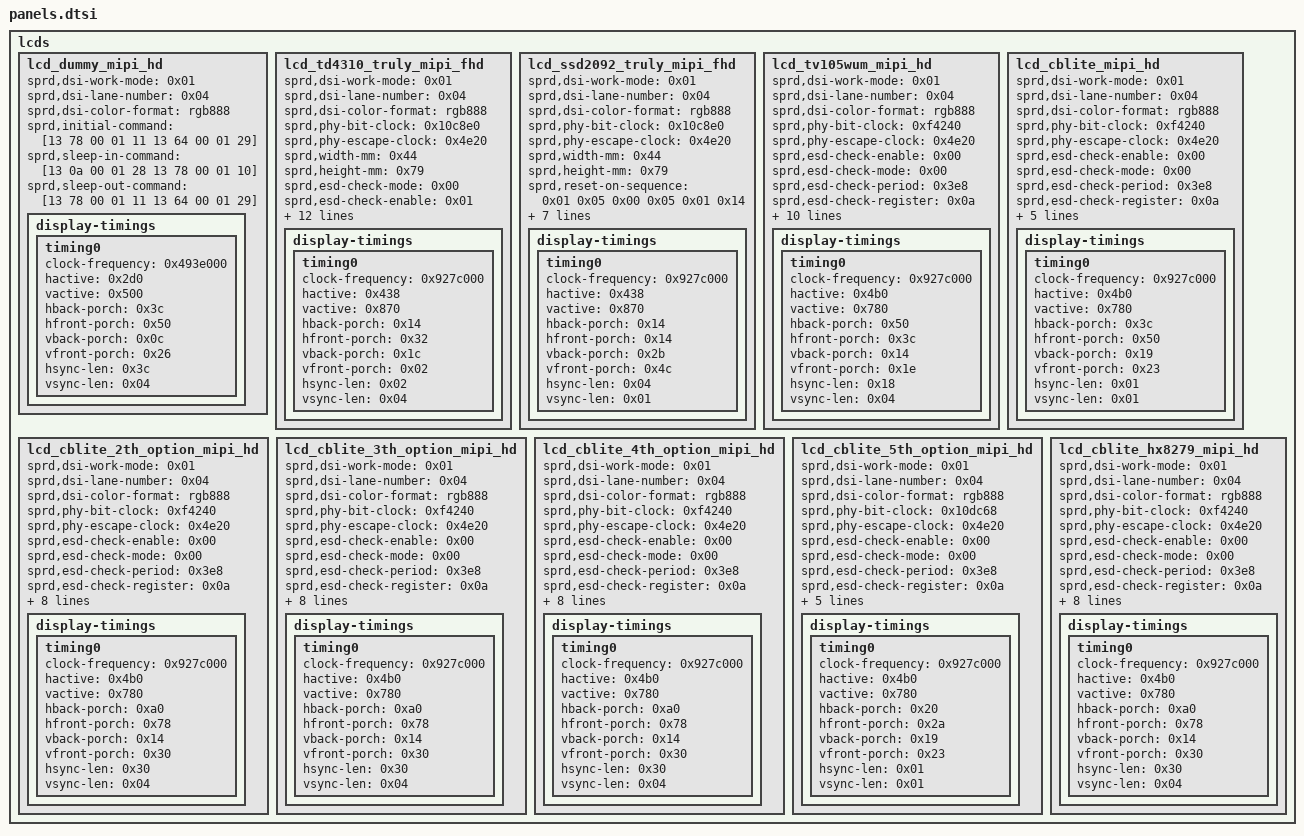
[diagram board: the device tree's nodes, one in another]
/*
 * iclass-c8pro hardware description; included in place from the board DTS.
 * Copyright (C) 2026 Evarentha - Linux 5.15 board port changes.
 */

	lcds {

		lcd_dummy_mipi_hd: lcd_dummy_mipi_hd {
			sprd,dsi-work-mode = <0x01>;
			sprd,dsi-lane-number = <0x04>;
			sprd,dsi-color-format = "rgb888";
			sprd,initial-command = [13 78 00 01 11 13 64 00 01 29];
			sprd,sleep-in-command = [13 0a 00 01 28 13 78 00 01 10];
			sprd,sleep-out-command = [13 78 00 01 11 13 64 00 01 29];
			phandle = <0x1ee>;

			display-timings {

				timing0 {
					clock-frequency = <0x493e000>;
					hactive = <0x2d0>;
					vactive = <0x500>;
					hback-porch = <0x3c>;
					hfront-porch = <0x50>;
					vback-porch = <0x0c>;
					vfront-porch = <0x26>;
					hsync-len = <0x3c>;
					vsync-len = <0x04>;
				};
			};
		};

		lcd_td4310_truly_mipi_fhd: lcd_td4310_truly_mipi_fhd {
			sprd,dsi-work-mode = <0x01>;
			sprd,dsi-lane-number = <0x04>;
			sprd,dsi-color-format = "rgb888";
			sprd,phy-bit-clock = <0x10c8e0>;
			sprd,phy-escape-clock = <0x4e20>;
			sprd,width-mm = <0x44>;
			sprd,height-mm = <0x79>;
			sprd,esd-check-mode = <0x00>;
			sprd,esd-check-enable = <0x01>;
			sprd,esd-check-register = <0x0a>;
			sprd,esd-check-value = <0x1c>;
			sprd,reset-on-sequence = <0x01 0x05 0x00 0x05 0x01 0x14>;
			sprd,reset-off-sequence = <0x00 0x05>;
			sprd,use-dcs-write;
			sprd,initial-command = [39 00 00 02 b0 00 39 00 00 04 b3 31 00 06 39 00 00 02 b4 00 39 00 00 06 b6 33 5b 81 72 00 39 00 00 08 b8 57 3d 19 1e 0a 50 50 39 00 00 08 b9 6f 3d 28 3c 14 c8 c8 39 00 00 08 ba b5 33 41 64 23 a0 a0 39 00 00 03 bb 14 14 39 00 00 03 bc 37 32 39 00 00 03 bd 64 32 39 00 00 02 be 04 39 00 00 02 c0 00 39 00 00 31 c1 04 40 00 00 26 15 19 0b 63 d2 d9 9a 73 ef bd e7 5c 6b 93 4d 22 18 8b 2a 41 00 00 00 00 00 00 00 00 00 40 02 22 1b 06 03 00 0f ff 00 01 00 00 00 39 00 00 19 c2 01 f8 70 08 68 08 0c 10 00 08 30 00 00 00 00 00 00 00 00 08 00 00 00 00 39 00 00 3f c3 86 d8 6d 86 d0 00 00 00 00 00 44 24 42 00 00 48 84 88 00 00 01 01 03 28 00 01 00 01 00 00 19 00 19 00 00 00 19 00 19 00 00 00 00 00 00 00 00 00 32 00 32 00 5a 02 00 00 00 00 00 00 40 00 39 00 00 15 c4 70 00 00 00 11 11 00 00 00 02 02 31 01 00 00 00 02 01 01 01 39 00 00 09 c5 08 00 00 00 00 70 00 00 39 00 00 40 c6 42 21 21 05 3d 05 3d 01 02 01 02 05 05 00 00 05 05 0b 0c 05 42 00 6e 61 00 00 00 00 00 00 00 00 00 00 00 00 00 00 00 00 00 00 00 00 00 00 00 00 00 00 00 00 00 00 00 00 00 00 00 00 00 00 00 39 00 00 27 c7 00 1f 30 43 52 5c 72 80 8b 95 45 4f 5c 70 79 85 90 93 bf 00 1f 30 43 52 5c 72 80 8b 95 45 4f 5c 70 79 85 90 93 bf 39 00 00 38 c8 00 00 00 00 00 fc 00 00 00 00 00 fc 00 00 00 00 00 fc 00 00 00 00 00 fc 00 00 00 00 00 fc 00 00 00 00 00 fc 00 00 00 00 00 fc 00 00 00 00 00 fc 00 00 00 00 00 fc 00 39 00 00 14 c9 00 00 00 00 00 fc 00 00 00 00 00 fc 00 00 00 00 00 fc 00 39 00 00 2c ca 1c fc fc fc 00 00 00 00 00 00 00 00 00 00 00 00 00 00 00 00 00 00 00 00 00 00 00 00 00 00 00 00 00 00 00 00 00 00 00 00 00 00 00 39 00 00 1c cb ff ff ff ff 0f 00 08 00 01 00 31 f0 40 08 00 00 00 00 00 00 00 00 00 00 00 00 00 39 00 00 03 cc 02 01 39 00 00 27 cd 25 00 28 00 28 00 5c 02 df df e0 e0 d6 d6 e0 e0 01 00 00 00 32 00 32 00 5d 02 24 24 01 33 00 33 00 5e 02 24 24 a2 39 00 00 1a ce 5d 40 49 53 59 5e 63 68 6e 74 7e 8a 98 a8 bb d0 ff 04 00 04 04 42 00 69 5a 39 00 00 03 cf 4a 1d 39 00 00 14 d0 33 57 d4 31 01 10 10 10 19 19 00 00 00 00 00 00 00 6d 65 39 00 00 02 d1 00 39 00 00 16 d3 1b 3b bb 77 77 77 bb b3 33 00 00 6d 6e c7 c7 33 bb f2 fd c6 0b 39 00 00 0b d5 03 00 00 02 0e 02 0e 01 00 00 39 00 00 02 d6 01 39 00 00 22 d7 f6 ff 03 05 41 24 80 1f c7 1f 1b 00 0c 07 20 00 00 00 00 00 0c 00 1f 00 fc 00 00 ab 67 7e 5d 26 00 39 00 00 08 d9 00 16 14 3f 0f 57 04 39 00 00 05 dd 30 06 23 65 39 00 00 05 de 00 3f ff 90 39 00 00 02 ea 1f 39 00 00 04 ee 41 51 00 39 00 00 04 f1 00 00 00 15 00 00 02 35 00 05 14 00 01 29 05 64 00 01 11];
			sprd,sleep-in-command = [13 0a 00 01 28 13 14 00 01 10];
			sprd,sleep-out-command = [13 78 00 01 11 13 32 00 01 29];
			phandle = <0x1ef>;

			display-timings {

				timing0 {
					clock-frequency = <0x927c000>;
					hactive = <0x438>;
					vactive = <0x870>;
					hback-porch = <0x14>;
					hfront-porch = <0x32>;
					vback-porch = <0x1c>;
					vfront-porch = <0x02>;
					hsync-len = <0x02>;
					vsync-len = <0x04>;
				};
			};
		};

		lcd_ssd2092_truly_mipi_fhd: lcd_ssd2092_truly_mipi_fhd {
			sprd,dsi-work-mode = <0x01>;
			sprd,dsi-lane-number = <0x04>;
			sprd,dsi-color-format = "rgb888";
			sprd,phy-bit-clock = <0x10c8e0>;
			sprd,phy-escape-clock = <0x4e20>;
			sprd,width-mm = <0x44>;
			sprd,height-mm = <0x79>;
			sprd,reset-on-sequence = <0x01 0x05 0x00 0x05 0x01 0x14>;
			sprd,reset-off-sequence = <0x00 0x05>;
			sprd,initial-command = [29 00 00 03 b5 00 00 29 00 00 03 b3 03 96 29 00 00 03 b4 21 ff 29 00 00 03 e1 00 00 29 00 00 04 e1 03 00 10 29 00 00 03 b0 04 01 29 00 00 03 b0 07 14 29 00 00 03 c6 04 2d 29 00 00 03 b9 0e 44 29 00 00 03 c1 0c 26 29 00 00 03 c1 08 99 29 00 00 03 b9 23 00 29 00 00 03 c2 04 0f 29 00 00 03 b9 11 22 29 00 00 03 b9 12 22 29 00 00 03 b9 13 22 29 00 00 03 b3 19 0b 29 00 00 03 b0 3d c8 29 00 00 03 b3 0f 20 29 00 00 02 36 02 29 00 00 03 c7 01 09 29 00 00 03 b3 15 80 29 00 00 03 b3 1e 02 29 00 00 03 b3 14 c0 29 00 00 03 b3 16 50 29 00 00 03 b3 1c e4 29 00 00 03 b3 28 09 29 00 00 03 b3 24 19 29 00 00 03 b0 12 00 29 00 00 03 b0 13 14 29 00 00 03 b0 1a 00 29 00 00 03 b0 1b 14 29 00 00 03 c1 0d 87 29 00 00 03 c1 0e 87 29 00 00 17 c3 00 10 2e 3e 48 5e 6b 7a 83 97 a3 a8 a5 ac ad b5 c1 c4 4e 4f 59 5a 29 00 00 17 c3 15 10 2e 3e 48 5e 6b 7a 83 97 a3 a8 a5 ac ad b5 c1 c4 4e 4f 59 5a 29 00 00 03 bb 01 8a 29 00 00 03 bb 02 23 29 00 00 03 bb 03 bc 29 00 00 03 bb 04 c0 29 00 00 03 bb 05 19 29 00 00 03 bb 06 37 29 00 00 03 bb 07 ee 29 00 00 03 bb 08 dd 29 00 00 03 bb 09 cc 29 00 00 03 bb 0a 36 29 00 00 03 bb 0b 70 29 00 00 03 bb 0c 00 29 00 00 03 bb 0d 8a 29 00 00 03 bb 0e 23 29 00 00 03 bb 0f bc 29 00 00 03 bb 10 c0 29 00 00 03 bb 11 18 29 00 00 03 bb 12 a7 29 00 00 03 bb 13 ee 29 00 00 03 bb 14 dd 29 00 00 03 bb 15 cc 29 00 00 03 bb 16 36 29 00 00 03 bb 17 70 29 00 00 03 bb 18 00 29 00 00 03 bb 31 01 29 00 00 03 bd 00 f0 29 00 00 03 bd 01 f0 29 00 00 03 bd 02 f0 29 00 00 03 bd 03 f0 29 00 00 03 bd 1a 02 29 00 00 03 bd 1b 24 29 00 00 03 bd 1d 01 29 00 00 03 bd 1e 01 29 00 00 03 bd 21 00 29 00 00 03 bd 1f 79 29 00 00 03 bd 20 14 29 00 00 03 bd 22 89 29 00 00 03 bd 23 13 29 00 00 03 bd 24 35 29 00 00 03 bd 26 01 29 00 00 03 bd 27 01 29 00 00 03 bd 2a 00 29 00 00 03 bd 28 79 29 00 00 03 bd 29 14 29 00 00 03 bd 2b 89 29 00 00 03 bd 2c 33 29 00 00 03 bd 2d 33 29 00 00 03 bd 2e 11 29 00 00 03 bd 2f 11 29 00 00 03 bd 31 22 29 00 00 03 bd 32 01 29 00 00 03 bd 33 04 29 00 00 03 bd 34 11 29 00 00 03 bd 35 11 29 00 00 03 bd 37 22 29 00 00 03 bd 38 01 29 00 00 03 bd 39 04 29 00 00 03 bd 3a 1e 29 00 00 03 bd 3b 1e 29 00 00 03 bd 3c 1e 29 00 00 03 bd 3d 1e 29 00 00 03 bd 40 aa 29 00 00 03 bd 42 1e 29 00 00 03 bd 43 1e 29 00 00 03 bd 44 1e 29 00 00 03 bd 45 1e 29 00 00 03 bd 48 aa 29 00 00 03 ba 02 05 29 00 00 03 ba 03 01 29 00 00 03 bc 1e 71 29 00 00 03 bc 24 83 29 00 00 03 b8 03 a9 29 00 00 03 ba 15 41 29 00 00 03 bb 19 8a 29 00 00 03 bb 1a 32 29 00 00 03 bb 1b bc 29 00 00 03 bb 1c c2 29 00 00 03 bb 1d 39 29 00 00 03 bb 1e 37 29 00 00 03 bb 1f ee 29 00 00 03 bb 20 dd 29 00 00 03 bb 21 cc 29 00 00 03 bb 22 36 29 00 00 03 bb 23 70 29 00 00 03 bb 24 00 29 00 00 03 bb 25 8a 29 00 00 03 bb 26 32 29 00 00 03 bb 27 bc 29 00 00 03 bb 28 c2 29 00 00 03 bb 29 38 29 00 00 03 bb 2a a7 29 00 00 03 bb 2b ee 29 00 00 03 bb 2c dd 29 00 00 03 bb 2d cc 29 00 00 03 bb 2e 36 29 00 00 03 bb 2f 70 29 00 00 03 bb 30 00 29 00 00 03 b8 15 a2 29 00 00 03 b0 39 00 29 00 00 04 c6 00 03 40 29 00 00 03 b3 18 00 29 00 00 03 ba 17 28 29 00 00 03 ba 23 15 29 00 00 03 b0 06 2c 29 00 00 03 ba 17 28 29 00 00 03 ba 23 15 29 00 00 03 ba 16 00 29 00 00 04 ba 28 02 02 29 00 00 03 ba 0f 8c 29 00 00 03 ba 10 0c 29 00 00 03 ba 11 23 29 00 00 05 ba 12 9d 9d 9d 29 00 00 03 ba 25 22 29 00 00 04 ba 0d 40 02 29 00 00 03 ba 2f 8c 29 00 00 03 c2 04 00 29 00 00 03 c2 05 c0 29 00 00 0b b9 11 00 00 00 00 00 00 00 00 00 29 00 00 03 ba 15 33 29 00 00 06 b9 00 5f 5f 61 0a 29 00 00 03 bd 08 07 29 00 00 03 bd 09 07 29 00 00 03 bc 03 00 29 00 00 03 bc 04 00 29 00 00 03 bc 05 00 29 00 00 03 bc 07 10 29 00 00 03 bc 08 10 29 00 00 03 bc 09 10 29 00 00 03 b9 11 00 29 00 00 03 b9 12 00 29 00 00 03 b9 13 00 29 00 00 03 b9 1d 00 29 00 00 03 b9 1e 00 29 00 00 03 b9 1f 00 29 00 00 03 c2 00 07 29 00 00 03 c1 0b 1f 29 00 00 03 b1 05 2f 29 00 00 02 35 00 29 00 00 04 b0 01 08 70 29 00 00 03 b9 25 a0 29 00 00 03 ba 2f cc 29 00 00 03 c1 02 b0 29 00 00 03 b3 1c c4 29 00 00 03 b3 1d 80 29 00 00 04 bd 11 02 22 29 00 00 02 36 0a 39 00 00 02 51 ff 39 00 00 02 53 2c 39 00 00 02 55 00 05 14 00 01 11 05 64 00 01 29];
			sprd,sleep-in-command = [13 0a 00 01 28 13 78 00 01 10];
			sprd,sleep-out-command = [13 78 00 01 11 13 32 00 01 29];
			phandle = <0x1f0>;

			display-timings {

				timing0 {
					clock-frequency = <0x927c000>;
					hactive = <0x438>;
					vactive = <0x870>;
					hback-porch = <0x14>;
					hfront-porch = <0x14>;
					vback-porch = <0x2b>;
					vfront-porch = <0x4c>;
					hsync-len = <0x04>;
					vsync-len = <0x01>;
				};
			};
		};

		lcd_tv105wum_mipi_hd: lcd_tv105wum_mipi_hd {
			sprd,dsi-work-mode = <0x01>;
			sprd,dsi-lane-number = <0x04>;
			sprd,dsi-color-format = "rgb888";
			sprd,phy-bit-clock = <0xf4240>;
			sprd,phy-escape-clock = <0x4e20>;
			sprd,esd-check-enable = <0x00>;
			sprd,esd-check-mode = <0x00>;
			sprd,esd-check-period = <0x3e8>;
			sprd,esd-check-register = <0x0a>;
			sprd,esd-check-value = <0x9c>;
			sprd,reset-on-sequence = <0x00 0x06 0x01 0x07>;
			sprd,reset-off-sequence = <0x00 0x06>;
			sprd,use-dcs-write;
			sprd,initial-command = [15 00 00 02 b0 05 15 00 00 02 b1 e5 15 00 00 02 b3 52 15 00 00 02 b0 00 15 00 00 02 b0 04 15 00 00 02 b8 00 15 00 00 02 b0 00 15 00 00 02 b6 03 15 00 00 02 b2 50 15 00 00 02 ba 87 15 00 00 02 bf 1f 15 00 00 02 c0 0f 15 00 00 02 c2 0c 15 00 00 02 c3 02 15 00 00 02 c4 0c 15 00 00 02 c5 02 15 00 00 02 b0 01 15 00 00 02 e0 26 15 00 00 02 e1 26 15 00 00 02 dc 00 15 00 00 02 dd 00 15 00 00 02 cc 26 15 00 00 02 cd 26 15 00 00 02 c8 00 15 00 00 02 c9 00 15 00 00 02 d2 04 15 00 00 02 d3 04 15 00 00 02 e6 03 15 00 00 02 e7 03 15 00 00 02 c4 08 15 00 00 02 c5 08 15 00 00 02 d8 07 15 00 00 02 d9 07 15 00 00 02 c2 06 15 00 00 02 c3 06 15 00 00 02 d6 05 15 00 00 02 d7 05 15 00 00 02 c0 0c 15 00 00 02 c1 0c 15 00 00 02 d4 0b 15 00 00 02 d5 0b 15 00 00 02 ca 0a 15 00 00 02 cb 0a 15 00 00 02 de 09 15 00 00 02 df 09 15 00 00 02 c6 26 15 00 00 02 c7 26 15 00 00 02 ce 00 15 00 00 02 cf 00 15 00 00 02 da 26 15 00 00 02 db 26 15 00 00 02 e2 00 15 00 00 02 e3 00 15 00 00 02 b0 02 15 00 00 02 c0 00 15 00 00 02 c1 0f 15 00 00 02 c2 1a 15 00 00 02 c3 2b 15 00 00 02 c4 38 15 00 00 02 c5 39 15 00 00 02 c6 38 15 00 00 02 c7 38 15 00 00 02 c8 36 15 00 00 02 c9 34 15 00 00 02 ca 35 15 00 00 02 cb 36 15 00 00 02 cc 39 15 00 00 02 cd 2d 15 00 00 02 ce 2e 15 00 00 02 cf 2f 15 00 00 02 d0 07 15 00 00 02 d2 00 15 00 00 02 d3 0f 15 00 00 02 d4 1a 15 00 00 02 d5 2b 15 00 00 02 d6 3b 15 00 00 02 d7 39 15 00 00 02 d8 38 15 00 00 02 d9 38 15 00 00 02 da 36 15 00 00 02 db 34 15 00 00 02 dc 35 15 00 00 02 dd 36 15 00 00 02 de 39 15 00 00 02 df 2d 15 00 00 02 e0 2e 15 00 00 02 e1 2f 15 00 00 02 e2 07 15 00 00 02 b0 03 15 00 00 02 c8 0b 15 00 00 02 c9 07 15 00 00 02 c3 00 15 00 00 02 e7 00 15 00 00 02 c5 2a 15 00 00 02 de 2a 15 00 00 02 ca 43 15 00 00 02 c9 07 15 00 00 02 e4 c0 15 00 00 02 e5 0d 15 00 00 02 cb 00 15 00 00 02 b0 06 15 00 00 02 b8 a5 15 00 00 02 c0 a5 15 00 00 02 c7 0f 15 00 00 02 d5 32 15 00 00 02 bc 33 15 00 00 02 b0 07 15 00 00 02 b1 04 15 00 00 02 b2 05 15 00 00 02 b3 0b 15 00 00 02 b4 1b 15 00 00 02 b5 2b 15 00 00 02 b6 38 15 00 00 02 b7 59 15 00 00 02 b8 76 15 00 00 02 b9 bb 15 00 00 02 ba fc 15 00 00 02 bb 77 15 00 00 02 bc f4 15 00 00 02 bd f8 15 00 00 02 be 6b 15 00 00 02 bf dc 15 00 00 02 c0 14 15 00 00 02 c1 49 15 00 00 02 c2 63 15 00 00 02 c3 7d 15 00 00 02 c4 8a 15 00 00 02 c5 96 15 00 00 02 c6 a2 15 00 00 02 c7 a8 15 00 00 02 c8 ac 15 00 00 02 c9 00 15 00 00 02 ca 00 15 00 00 02 cb 05 15 00 00 02 cc 6b 15 00 00 02 cd ff 15 00 00 02 ce ff 15 00 00 02 b0 08 15 00 00 02 b1 04 15 00 00 02 b2 05 15 00 00 02 b3 0d 15 00 00 02 b4 1e 15 00 00 02 b5 2f 15 00 00 02 b6 40 15 00 00 02 b7 63 15 00 00 02 b8 86 15 00 00 02 b9 d1 15 00 00 02 ba 19 15 00 00 02 bb 9e 15 00 00 02 bc 2a 15 00 00 02 bd 2d 15 00 00 02 be ad 15 00 00 02 bf 27 15 00 00 02 c0 62 15 00 00 02 c1 9a 15 00 00 02 c2 b5 15 00 00 02 c3 d0 15 00 00 02 c4 dc 15 00 00 02 c5 e8 15 00 00 02 c6 f4 15 00 00 02 c7 fa 15 00 00 02 c8 fc 15 00 00 02 c9 00 15 00 00 02 ca 00 15 00 00 02 cb 16 15 00 00 02 cc af 15 00 00 02 cd ff 15 00 00 02 ce ff 15 00 00 02 b0 09 15 00 00 02 b1 04 15 00 00 02 b2 04 15 00 00 02 b3 0b 15 00 00 02 b4 1c 15 00 00 02 b5 2c 15 00 00 02 b6 3c 15 00 00 02 b7 5d 15 00 00 02 b8 7e 15 00 00 02 b9 c7 15 00 00 02 ba 0c 15 00 00 02 bb 8b 15 00 00 02 bc 11 15 00 00 02 bd 15 15 00 00 02 be 8d 15 00 00 02 bf 02 15 00 00 02 c0 39 15 00 00 02 c1 6f 15 00 00 02 c2 89 15 00 00 02 c3 a2 15 00 00 02 c4 ae 15 00 00 02 c5 bb 15 00 00 02 c6 c6 15 00 00 02 c7 cc 15 00 00 02 c8 d0 15 00 00 02 c9 00 15 00 00 02 ca 00 15 00 00 02 cb 16 15 00 00 02 cc af 15 00 00 02 cd ff 15 00 00 02 ce ff 15 00 00 02 b0 0a 15 00 00 02 b1 04 15 00 00 02 b2 05 15 00 00 02 b3 0b 15 00 00 02 b4 1b 15 00 00 02 b5 2b 15 00 00 02 b6 38 15 00 00 02 b7 59 15 00 00 02 b8 76 15 00 00 02 b9 bb 15 00 00 02 ba fc 15 00 00 02 bb 77 15 00 00 02 bc f4 15 00 00 02 bd f8 15 00 00 02 be 6b 15 00 00 02 bf dc 15 00 00 02 c0 14 15 00 00 02 c1 49 15 00 00 02 c2 63 15 00 00 02 c3 7d 15 00 00 02 c4 8a 15 00 00 02 c5 96 15 00 00 02 c6 a2 15 00 00 02 c7 a8 15 00 00 02 c8 ac 15 00 00 02 c9 00 15 00 00 02 ca 00 15 00 00 02 cb 05 15 00 00 02 cc 6b 15 00 00 02 cd ff 15 00 00 02 ce ff 15 00 00 02 b0 0b 15 00 00 02 b1 04 15 00 00 02 b2 05 15 00 00 02 b3 0d 15 00 00 02 b4 1e 15 00 00 02 b5 2f 15 00 00 02 b6 40 15 00 00 02 b7 63 15 00 00 02 b8 86 15 00 00 02 b9 d1 15 00 00 02 ba 19 15 00 00 02 bb 9e 15 00 00 02 bc 2a 15 00 00 02 bd 2d 15 00 00 02 be ad 15 00 00 02 bf 27 15 00 00 02 c0 62 15 00 00 02 c1 9a 15 00 00 02 c2 b5 15 00 00 02 c3 d0 15 00 00 02 c4 dc 15 00 00 02 c5 e8 15 00 00 02 c6 f4 15 00 00 02 c7 fa 15 00 00 02 c8 fc 15 00 00 02 c9 00 15 00 00 02 ca 00 15 00 00 02 cb 16 15 00 00 02 cc af 15 00 00 02 cd ff 15 00 00 02 ce ff 15 00 00 02 b0 0c 15 00 00 02 b1 04 15 00 00 02 b2 04 15 00 00 02 b3 0b 15 00 00 02 b4 1c 15 00 00 02 b5 2c 15 00 00 02 b6 3c 15 00 00 02 b7 5d 15 00 00 02 b8 7e 15 00 00 02 b9 c7 15 00 00 02 ba 0c 15 00 00 02 bb 8b 15 00 00 02 bc 11 15 00 00 02 bd 15 15 00 00 02 be 8d 15 00 00 02 bf 02 15 00 00 02 c0 39 15 00 00 02 c1 6f 15 00 00 02 c2 89 15 00 00 02 c3 a2 15 00 00 02 c4 ae 15 00 00 02 c5 bb 15 00 00 02 c6 c6 15 00 00 02 c7 cc 15 00 00 02 c8 d0 15 00 00 02 c9 00 15 00 00 02 ca 00 15 00 00 02 cb 16 15 00 00 02 cc af 15 00 00 02 cd ff 15 00 00 02 ce ff 15 00 00 02 b0 00 15 00 00 02 b3 08 15 00 00 02 b0 04 15 0a 00 02 b8 68 05 64 00 01 11 05 32 00 01 29];
			sprd,sleep-in-command = [13 0a 00 01 28 13 65 00 01 10];
			sprd,sleep-out-command = [13 64 00 01 11 13 32 00 01 29];
			phandle = <0x1f1>;

			display-timings {

				timing0 {
					clock-frequency = <0x927c000>;
					hactive = <0x4b0>;
					vactive = <0x780>;
					hback-porch = <0x50>;
					hfront-porch = <0x3c>;
					vback-porch = <0x14>;
					vfront-porch = <0x1e>;
					hsync-len = <0x18>;
					vsync-len = <0x04>;
				};
			};
		};

		lcd_cblite_mipi_hd: lcd_cblite_mipi_hd {
			sprd,dsi-work-mode = <0x01>;
			sprd,dsi-lane-number = <0x04>;
			sprd,dsi-color-format = "rgb888";
			sprd,phy-bit-clock = <0xf4240>;
			sprd,phy-escape-clock = <0x4e20>;
			sprd,esd-check-enable = <0x00>;
			sprd,esd-check-mode = <0x00>;
			sprd,esd-check-period = <0x3e8>;
			sprd,esd-check-register = <0x0a>;
			sprd,esd-check-value = <0x9c>;
			sprd,reset-on-sequence = <0x00 0x32 0x01 0x32>;
			sprd,reset-off-sequence = <0x00 0x32>;
			sprd,use-dcs-write;
			sprd,initial-command;
			phandle = <0x1f2>;

			display-timings {

				timing0 {
					clock-frequency = <0x927c000>;
					hactive = <0x4b0>;
					vactive = <0x780>;
					hback-porch = <0x3c>;
					hfront-porch = <0x50>;
					vback-porch = <0x19>;
					vfront-porch = <0x23>;
					hsync-len = <0x01>;
					vsync-len = <0x01>;
				};
			};
		};

		lcd_cblite_2th_option_mipi_hd: lcd_cblite_2th_option_mipi_hd {
			sprd,dsi-work-mode = <0x01>;
			sprd,dsi-lane-number = <0x04>;
			sprd,dsi-color-format = "rgb888";
			sprd,phy-bit-clock = <0xf4240>;
			sprd,phy-escape-clock = <0x4e20>;
			sprd,esd-check-enable = <0x00>;
			sprd,esd-check-mode = <0x00>;
			sprd,esd-check-period = <0x3e8>;
			sprd,esd-check-register = <0x0a>;
			sprd,esd-check-value = <0x9c>;
			sprd,reset-on-sequence = <0x00 0x06 0x01 0x07>;
			sprd,reset-off-sequence = <0x00 0x06>;
			sprd,use-dcs-write;
			sprd,initial-command = [05 22 00 01 10 15 00 00 02 b0 05 15 00 00 02 b1 e5 15 00 00 02 b3 52 15 00 00 02 b0 00 15 00 00 02 b3 88 15 00 00 02 b0 04 15 00 00 02 b8 00 15 00 00 02 b0 00 15 00 00 02 b6 03 15 00 00 02 ba 87 15 00 00 02 bf 15 15 00 00 02 c0 12 15 00 00 02 c2 0c 15 00 00 02 c3 02 15 00 00 02 c4 0c 15 00 00 02 c5 02 15 00 00 02 b0 01 15 00 00 02 c0 0c 15 00 00 02 c1 0c 15 00 00 02 c2 06 15 00 00 02 c3 06 15 00 00 02 c4 08 15 00 00 02 c5 08 15 00 00 02 c6 26 15 00 00 02 c7 26 15 00 00 02 c8 00 15 00 00 02 c9 00 15 00 00 02 ca 0a 15 00 00 02 cb 0a 15 00 00 02 cc 26 15 00 00 02 cd 26 15 00 00 02 ce 00 15 00 00 02 cf 00 15 00 00 02 d0 00 15 00 00 02 d1 00 15 00 00 02 d2 04 15 00 00 02 d3 04 15 00 00 02 d4 0b 15 00 00 02 d5 0b 15 00 00 02 d6 05 15 00 00 02 d7 05 15 00 00 02 d8 07 15 00 00 02 d9 07 15 00 00 02 da 26 15 00 00 02 db 26 15 00 00 02 dc 00 15 00 00 02 dd 00 15 00 00 02 de 09 15 00 00 02 df 09 15 00 00 02 e0 26 15 00 00 02 e1 26 15 00 00 02 e2 00 15 00 00 02 e3 00 15 00 00 02 e4 00 15 00 00 02 e5 00 15 00 00 02 e6 03 15 00 00 02 e7 03 15 00 00 02 b0 02 15 00 00 02 c0 00 15 00 00 02 c1 07 15 00 00 02 c2 10 15 00 00 02 c3 1f 15 00 00 02 c4 32 15 00 00 02 c5 35 15 00 00 02 c6 38 15 00 00 02 c7 3a 15 00 00 02 c8 3e 15 00 00 02 c9 3f 15 00 00 02 ca 3f 15 00 00 02 cb 3f 15 00 00 02 cc 3f 15 00 00 02 cd 37 15 00 00 02 ce 36 15 00 00 02 cf 34 15 00 00 02 d0 07 15 00 00 02 d2 00 15 00 00 02 d3 07 15 00 00 02 d4 10 15 00 00 02 d5 1f 15 00 00 02 d6 32 15 00 00 02 d7 35 15 00 00 02 d8 38 15 00 00 02 d9 3a 15 00 00 02 da 3e 15 00 00 02 db 3f 15 00 00 02 dc 3f 15 00 00 02 dd 3f 15 00 00 02 de 3f 15 00 00 02 df 37 15 00 00 02 e0 36 15 00 00 02 e1 34 15 00 00 02 e2 07 15 00 00 02 b0 03 15 00 00 02 c8 0b 15 00 00 02 c9 07 15 00 00 02 c3 00 15 00 00 02 e7 00 15 00 00 02 c5 2a 15 00 00 02 de 2a 15 00 00 02 ca 43 15 00 00 02 c9 07 15 00 00 02 e4 c0 15 00 00 02 e5 0d 15 00 00 02 cb 28 15 00 00 02 b0 06 15 00 00 02 b8 a5 15 00 00 02 c0 a5 15 00 00 02 c7 0f 15 00 00 02 d5 32 15 00 00 02 bc 33 15 00 00 02 b0 07 15 00 00 02 b1 08 15 00 00 02 b2 08 15 00 00 02 b3 11 15 00 00 02 b4 24 15 00 00 02 b5 37 15 00 00 02 b6 48 15 00 00 02 b7 60 15 00 00 02 b8 79 15 00 00 02 b9 b9 15 00 00 02 ba f8 15 00 00 02 bb 71 15 00 00 02 bc e9 15 00 00 02 bd ed 15 00 00 02 be 67 15 00 00 02 bf e4 15 00 00 02 c0 25 15 00 00 02 c1 63 15 00 00 02 c2 84 15 00 00 02 c3 9c 15 00 00 02 c4 a6 15 00 00 02 c5 b1 15 00 00 02 c6 bd 15 00 00 02 c7 c4 15 00 00 02 c8 c8 15 00 00 02 c9 00 15 00 00 02 ca 00 15 00 00 02 cb 05 15 00 00 02 cc 6b 15 00 00 02 cd ff 15 00 00 02 ce ff 15 00 00 02 b0 08 15 00 00 02 b1 04 15 00 00 02 b2 06 15 00 00 02 b3 11 15 00 00 02 b4 24 15 00 00 02 b5 38 15 00 00 02 b6 49 15 00 00 02 b7 61 15 00 00 02 b8 79 15 00 00 02 b9 b9 15 00 00 02 ba f8 15 00 00 02 bb 71 15 00 00 02 bc ea 15 00 00 02 bd ed 15 00 00 02 be 68 15 00 00 02 bf e5 15 00 00 02 c0 26 15 00 00 02 c1 64 15 00 00 02 c2 85 15 00 00 02 c3 9c 15 00 00 02 c4 a7 15 00 00 02 c5 b1 15 00 00 02 c6 bd 15 00 00 02 c7 c4 15 00 00 02 c8 c8 15 00 00 02 c9 00 15 00 00 02 ca 00 15 00 00 02 cb 05 15 00 00 02 cc 6b 15 00 00 02 cd ff 15 00 00 02 ce ff 15 00 00 02 b0 09 15 00 00 02 b1 0c 15 00 00 02 b2 0c 15 00 00 02 b3 0f 15 00 00 02 b4 23 15 00 00 02 b5 37 15 00 00 02 b6 48 15 00 00 02 b7 60 15 00 00 02 b8 77 15 00 00 02 b9 b8 15 00 00 02 ba f7 15 00 00 02 bb 6f 15 00 00 02 bc e6 15 00 00 02 bd ea 15 00 00 02 be 62 15 00 00 02 bf da 15 00 00 02 c0 1a 15 00 00 02 c1 56 15 00 00 02 c2 75 15 00 00 02 c3 91 15 00 00 02 c4 9c 15 00 00 02 c5 a5 15 00 00 02 c6 af 15 00 00 02 c7 b5 15 00 00 02 c8 b8 15 00 00 02 c9 00 15 00 00 02 ca 00 15 00 00 02 cb 05 15 00 00 02 cc 6b 15 00 00 02 cd ff 15 00 00 02 ce ff 15 00 00 02 b0 0a 15 00 00 02 b1 08 15 00 00 02 b2 08 15 00 00 02 b3 11 15 00 00 02 b4 24 15 00 00 02 b5 37 15 00 00 02 b6 48 15 00 00 02 b7 60 15 00 00 02 b8 79 15 00 00 02 b9 b9 15 00 00 02 ba f8 15 00 00 02 bb 71 15 00 00 02 bc e9 15 00 00 02 bd ed 15 00 00 02 be 67 15 00 00 02 bf e4 15 00 00 02 c0 25 15 00 00 02 c1 63 15 00 00 02 c2 84 15 00 00 02 c3 9c 15 00 00 02 c4 a6 15 00 00 02 c5 b1 15 00 00 02 c6 bd 15 00 00 02 c7 c4 15 00 00 02 c8 c8 15 00 00 02 c9 00 15 00 00 02 ca 00 15 00 00 02 cb 05 15 00 00 02 cc 6b 15 00 00 02 cd ff 15 00 00 02 ce ff 15 00 00 02 b0 0b 15 00 00 02 b1 04 15 00 00 02 b2 06 15 00 00 02 b3 11 15 00 00 02 b4 24 15 00 00 02 b5 38 15 00 00 02 b6 49 15 00 00 02 b7 61 15 00 00 02 b8 79 15 00 00 02 b9 b9 15 00 00 02 ba f8 15 00 00 02 bb 71 15 00 00 02 bc ea 15 00 00 02 bd ed 15 00 00 02 be 68 15 00 00 02 bf e5 15 00 00 02 c0 26 15 00 00 02 c1 64 15 00 00 02 c2 85 15 00 00 02 c3 9c 15 00 00 02 c4 a7 15 00 00 02 c5 b1 15 00 00 02 c6 bd 15 00 00 02 c7 c4 15 00 00 02 c8 c8 15 00 00 02 c9 00 15 00 00 02 ca 00 15 00 00 02 cb 05 15 00 00 02 cc 6b 15 00 00 02 cd ff 15 00 00 02 ce ff 15 00 00 02 b0 0c 15 00 00 02 b1 0c 15 00 00 02 b2 0c 15 00 00 02 b3 0f 15 00 00 02 b4 23 15 00 00 02 b5 37 15 00 00 02 b6 48 15 00 00 02 b7 60 15 00 00 02 b8 77 15 00 00 02 b9 b8 15 00 00 02 ba f7 15 00 00 02 bb 6f 15 00 00 02 bc e6 15 00 00 02 bd ea 15 00 00 02 be 62 15 00 00 02 bf da 15 00 00 02 c0 1a 15 00 00 02 c1 56 15 00 00 02 c2 75 15 00 00 02 c3 91 15 00 00 02 c4 9c 15 00 00 02 c5 a5 15 00 00 02 c6 af 15 00 00 02 c7 b5 15 00 00 02 c8 b8 15 00 00 02 c9 00 15 00 00 02 ca 00 15 00 00 02 cb 05 15 00 00 02 cc 6b 15 00 00 02 cd ff 15 00 00 02 ce ff 15 00 00 02 b0 00 15 00 00 02 b2 50 15 00 00 02 b3 08 15 00 00 02 b0 04 15 0a 00 02 b8 68 05 64 00 01 11 05 32 00 01 29];
			sprd,sleep-in-command = [05 0a 00 01 28 05 65 00 01 10];
			phandle = <0x1f3>;

			display-timings {

				timing0 {
					clock-frequency = <0x927c000>;
					hactive = <0x4b0>;
					vactive = <0x780>;
					hback-porch = <0xa0>;
					hfront-porch = <0x78>;
					vback-porch = <0x14>;
					vfront-porch = <0x30>;
					hsync-len = <0x30>;
					vsync-len = <0x04>;
				};
			};
		};

		lcd_cblite_3th_option_mipi_hd: lcd_cblite_3th_option_mipi_hd {
			sprd,dsi-work-mode = <0x01>;
			sprd,dsi-lane-number = <0x04>;
			sprd,dsi-color-format = "rgb888";
			sprd,phy-bit-clock = <0xf4240>;
			sprd,phy-escape-clock = <0x4e20>;
			sprd,esd-check-enable = <0x00>;
			sprd,esd-check-mode = <0x00>;
			sprd,esd-check-period = <0x3e8>;
			sprd,esd-check-register = <0x0a>;
			sprd,esd-check-value = <0x9c>;
			sprd,reset-on-sequence = <0x00 0x06 0x01 0x07>;
			sprd,reset-off-sequence = <0x00 0x06>;
			sprd,use-dcs-write;
			sprd,initial-command = [05 22 00 01 10 15 00 00 02 b0 05 15 00 00 02 b3 52 15 00 00 02 bc 20 15 00 00 02 b0 01 15 00 00 02 e0 26 15 00 00 02 e1 26 15 00 00 02 dc 00 15 00 00 02 dd 00 15 00 00 02 cc 26 15 00 00 02 cd 26 15 00 00 02 c8 00 15 00 00 02 c9 00 15 00 00 02 d2 03 15 00 00 02 d3 03 15 00 00 02 e6 04 15 00 00 02 e7 04 15 00 00 02 c4 09 15 00 00 02 c5 09 15 00 00 02 d8 0a 15 00 00 02 d9 0a 15 00 00 02 c2 0b 15 00 00 02 c3 0b 15 00 00 02 d6 0c 15 00 00 02 d7 0c 15 00 00 02 c0 05 15 00 00 02 c1 05 15 00 00 02 d4 06 15 00 00 02 d5 06 15 00 00 02 ca 07 15 00 00 02 cb 07 15 00 00 02 de 08 15 00 00 02 df 08 15 00 00 02 b0 03 15 00 00 02 c8 0b 15 00 00 02 c9 07 15 00 00 02 c3 00 15 00 00 02 e7 00 15 00 00 02 c5 2a 15 00 00 02 de 2a 15 00 00 02 ca 43 15 00 00 02 e4 c0 15 00 00 02 e5 0d 15 00 00 02 cb 28 15 00 00 02 b0 00 15 00 00 02 bf 19 15 00 00 02 c0 0f 15 00 00 02 c2 09 15 00 00 02 c3 02 15 00 00 02 c4 0f 15 00 00 02 c5 02 15 00 00 02 b0 02 15 00 00 02 c0 00 15 00 00 02 c1 04 15 00 00 02 c2 15 15 00 00 02 c3 26 15 00 00 02 c4 2a 15 00 00 02 c5 2f 15 00 00 02 c6 32 15 00 00 02 c7 36 15 00 00 02 c8 3a 15 00 00 02 c9 37 15 00 00 02 ca 38 15 00 00 02 cb 37 15 00 00 02 cc 3f 15 00 00 02 cd 32 15 00 00 02 ce 34 15 00 00 02 cf 33 15 00 00 02 d0 07 15 00 00 02 d2 04 15 00 00 02 d3 0b 15 00 00 02 d4 17 15 00 00 02 d5 2b 15 00 00 02 d6 38 15 00 00 02 d7 3b 15 00 00 02 d8 3d 15 00 00 02 d9 3e 15 00 00 02 da 3e 15 00 00 02 db 3f 15 00 00 02 dc 3f 15 00 00 02 dd 3f 15 00 00 02 de 3f 15 00 00 02 df 32 15 00 00 02 e0 30 15 00 00 02 e1 2f 15 00 00 02 e2 00 15 00 00 02 b0 06 15 00 00 02 b8 a5 15 00 00 02 bc 00 15 00 00 02 c0 a5 15 00 00 02 c7 0f 15 00 00 02 d5 32 15 00 00 02 b8 00 15 00 00 02 c0 00 15 00 00 02 36 03 05 c8 00 01 11 05 64 00 01 29];
			sprd,sleep-in-command = [05 0a 00 01 28 05 65 00 01 10];
			phandle = <0x1f4>;

			display-timings {

				timing0 {
					clock-frequency = <0x927c000>;
					hactive = <0x4b0>;
					vactive = <0x780>;
					hback-porch = <0xa0>;
					hfront-porch = <0x78>;
					vback-porch = <0x14>;
					vfront-porch = <0x30>;
					hsync-len = <0x30>;
					vsync-len = <0x04>;
				};
			};
		};

		lcd_cblite_4th_option_mipi_hd: lcd_cblite_4th_option_mipi_hd {
			sprd,dsi-work-mode = <0x01>;
			sprd,dsi-lane-number = <0x04>;
			sprd,dsi-color-format = "rgb888";
			sprd,phy-bit-clock = <0xf4240>;
			sprd,phy-escape-clock = <0x4e20>;
			sprd,esd-check-enable = <0x00>;
			sprd,esd-check-mode = <0x00>;
			sprd,esd-check-period = <0x3e8>;
			sprd,esd-check-register = <0x0a>;
			sprd,esd-check-value = <0x9c>;
			sprd,reset-on-sequence = <0x00 0x06 0x01 0x07>;
			sprd,reset-off-sequence = <0x00 0x06>;
			sprd,use-dcs-write;
			sprd,initial-command = [05 22 00 01 10 15 00 00 02 b0 05 15 00 00 02 b3 52 15 00 00 02 bc 20 15 00 00 02 b0 01 15 00 00 02 e0 26 15 00 00 02 e1 26 15 00 00 02 dc 00 15 00 00 02 dd 00 15 00 00 02 cc 26 15 00 00 02 cd 26 15 00 00 02 c8 00 15 00 00 02 c9 00 15 00 00 02 d2 03 15 00 00 02 d3 03 15 00 00 02 e6 04 15 00 00 02 e7 04 15 00 00 02 c4 09 15 00 00 02 c5 09 15 00 00 02 d8 0a 15 00 00 02 d9 0a 15 00 00 02 c2 0b 15 00 00 02 c3 0b 15 00 00 02 d6 0c 15 00 00 02 d7 0c 15 00 00 02 c0 05 15 00 00 02 c1 05 15 00 00 02 d4 06 15 00 00 02 d5 06 15 00 00 02 ca 07 15 00 00 02 cb 07 15 00 00 02 de 08 15 00 00 02 df 08 15 00 00 02 b0 03 15 00 00 02 c8 0b 15 00 00 02 c9 07 15 00 00 02 c3 00 15 00 00 02 e7 00 15 00 00 02 c5 2a 15 00 00 02 de 2a 15 00 00 02 ca 43 15 00 00 02 e4 c0 15 00 00 02 e5 0d 15 00 00 02 cb 28 15 00 00 02 b0 00 15 00 00 02 bf 19 15 00 00 02 c0 0f 15 00 00 02 c2 09 15 00 00 02 c3 02 15 00 00 02 c4 0f 15 00 00 02 c5 02 15 00 00 02 b0 02 15 00 00 02 c0 00 15 00 00 02 c1 04 15 00 00 02 c2 15 15 00 00 02 c3 26 15 00 00 02 c4 2a 15 00 00 02 c5 2f 15 00 00 02 c6 32 15 00 00 02 c7 36 15 00 00 02 c8 3a 15 00 00 02 c9 37 15 00 00 02 ca 38 15 00 00 02 cb 37 15 00 00 02 cc 3f 15 00 00 02 cd 32 15 00 00 02 ce 34 15 00 00 02 cf 33 15 00 00 02 d0 07 15 00 00 02 d2 04 15 00 00 02 d3 0b 15 00 00 02 d4 17 15 00 00 02 d5 2b 15 00 00 02 d6 38 15 00 00 02 d7 3b 15 00 00 02 d8 3d 15 00 00 02 d9 3e 15 00 00 02 da 3e 15 00 00 02 db 3f 15 00 00 02 dc 3f 15 00 00 02 dd 3f 15 00 00 02 de 3f 15 00 00 02 df 32 15 00 00 02 e0 30 15 00 00 02 e1 2f 15 00 00 02 e2 00 15 00 00 02 b0 06 15 00 00 02 b8 a5 15 00 00 02 bc 00 15 00 00 02 c0 a5 15 00 00 02 c7 0f 15 00 00 02 d5 32 15 00 00 02 b8 00 15 00 00 02 c0 00 15 00 00 02 36 03 05 c8 00 01 11 05 64 00 01 29];
			sprd,sleep-in-command = [05 0a 00 01 28 05 65 00 01 10];
			phandle = <0x1f5>;

			display-timings {

				timing0 {
					clock-frequency = <0x927c000>;
					hactive = <0x4b0>;
					vactive = <0x780>;
					hback-porch = <0xa0>;
					hfront-porch = <0x78>;
					vback-porch = <0x14>;
					vfront-porch = <0x30>;
					hsync-len = <0x30>;
					vsync-len = <0x04>;
				};
			};
		};

		lcd_cblite_5th_option_mipi_hd: lcd_cblite_5th_option_mipi_hd {
			sprd,dsi-work-mode = <0x01>;
			sprd,dsi-lane-number = <0x04>;
			sprd,dsi-color-format = "rgb888";
			sprd,phy-bit-clock = <0x10dc68>;
			sprd,phy-escape-clock = <0x4e20>;
			sprd,esd-check-enable = <0x00>;
			sprd,esd-check-mode = <0x00>;
			sprd,esd-check-period = <0x3e8>;
			sprd,esd-check-register = <0x0a>;
			sprd,esd-check-value = <0x9c>;
			sprd,reset-on-sequence = <0x00 0x32 0x01 0x32>;
			sprd,reset-off-sequence = <0x00 0x32>;
			sprd,use-dcs-write;
			sprd,initial-command;
			phandle = <0x1f6>;

			display-timings {

				timing0 {
					clock-frequency = <0x927c000>;
					hactive = <0x4b0>;
					vactive = <0x780>;
					hback-porch = <0x20>;
					hfront-porch = <0x2a>;
					vback-porch = <0x19>;
					vfront-porch = <0x23>;
					hsync-len = <0x01>;
					vsync-len = <0x01>;
				};
			};
		};

		lcd_cblite_hx8279_mipi_hd: lcd_cblite_hx8279_mipi_hd {
			sprd,dsi-work-mode = <0x01>;
			sprd,dsi-lane-number = <0x04>;
			sprd,dsi-color-format = "rgb888";
			sprd,phy-bit-clock = <0xf4240>;
			sprd,phy-escape-clock = <0x4e20>;
			sprd,esd-check-enable = <0x00>;
			sprd,esd-check-mode = <0x00>;
			sprd,esd-check-period = <0x3e8>;
			sprd,esd-check-register = <0x0a>;
			sprd,esd-check-value = <0x9c>;
			sprd,reset-on-sequence = <0x00 0x06 0x01 0x07>;
			sprd,reset-off-sequence = <0x00 0x06>;
			sprd,use-dcs-write;
			sprd,initial-command = [05 22 00 01 10 15 00 00 02 b0 05 15 00 00 02 b1 e5 15 00 00 02 b3 52 15 00 00 02 b0 00 15 00 00 02 b3 88 15 00 00 02 b0 04 15 00 00 02 b8 00 15 00 00 02 b0 00 15 00 00 02 b6 03 15 00 00 02 ba 87 15 00 00 02 bf 15 15 00 00 02 c0 12 15 00 00 02 c2 0c 15 00 00 02 c3 02 15 00 00 02 c4 0c 15 00 00 02 c5 02 15 00 00 02 b0 01 15 00 00 02 c0 0c 15 00 00 02 c1 0c 15 00 00 02 c2 06 15 00 00 02 c3 06 15 00 00 02 c4 08 15 00 00 02 c5 08 15 00 00 02 c6 26 15 00 00 02 c7 26 15 00 00 02 c8 00 15 00 00 02 c9 00 15 00 00 02 ca 0a 15 00 00 02 cb 0a 15 00 00 02 cc 26 15 00 00 02 cd 26 15 00 00 02 ce 00 15 00 00 02 cf 00 15 00 00 02 d0 00 15 00 00 02 d1 00 15 00 00 02 d2 04 15 00 00 02 d3 04 15 00 00 02 d4 0b 15 00 00 02 d5 0b 15 00 00 02 d6 05 15 00 00 02 d7 05 15 00 00 02 d8 07 15 00 00 02 d9 07 15 00 00 02 da 26 15 00 00 02 db 26 15 00 00 02 dc 00 15 00 00 02 dd 00 15 00 00 02 de 09 15 00 00 02 df 09 15 00 00 02 e0 26 15 00 00 02 e1 26 15 00 00 02 e2 00 15 00 00 02 e3 00 15 00 00 02 e4 00 15 00 00 02 e5 00 15 00 00 02 e6 03 15 00 00 02 e7 03 15 00 00 02 b0 02 15 00 00 02 c0 00 15 00 00 02 c1 07 15 00 00 02 c2 10 15 00 00 02 c3 1f 15 00 00 02 c4 32 15 00 00 02 c5 35 15 00 00 02 c6 38 15 00 00 02 c7 3a 15 00 00 02 c8 3e 15 00 00 02 c9 3f 15 00 00 02 ca 3f 15 00 00 02 cb 3f 15 00 00 02 cc 3f 15 00 00 02 cd 37 15 00 00 02 ce 36 15 00 00 02 cf 34 15 00 00 02 d0 07 15 00 00 02 d2 00 15 00 00 02 d3 07 15 00 00 02 d4 10 15 00 00 02 d5 1f 15 00 00 02 d6 32 15 00 00 02 d7 35 15 00 00 02 d8 38 15 00 00 02 d9 3a 15 00 00 02 da 3e 15 00 00 02 db 3f 15 00 00 02 dc 3f 15 00 00 02 dd 3f 15 00 00 02 de 3f 15 00 00 02 df 37 15 00 00 02 e0 36 15 00 00 02 e1 34 15 00 00 02 e2 07 15 00 00 02 b0 03 15 00 00 02 c8 0b 15 00 00 02 c9 07 15 00 00 02 c3 00 15 00 00 02 e7 00 15 00 00 02 c5 2a 15 00 00 02 de 2a 15 00 00 02 ca 43 15 00 00 02 c9 07 15 00 00 02 e4 c0 15 00 00 02 e5 0d 15 00 00 02 cb 28 15 00 00 02 b0 06 15 00 00 02 b8 a5 15 00 00 02 c0 a5 15 00 00 02 c7 0f 15 00 00 02 d5 32 15 00 00 02 bc 33 15 00 00 02 b0 07 15 00 00 02 b1 08 15 00 00 02 b2 08 15 00 00 02 b3 11 15 00 00 02 b4 24 15 00 00 02 b5 37 15 00 00 02 b6 48 15 00 00 02 b7 60 15 00 00 02 b8 79 15 00 00 02 b9 b9 15 00 00 02 ba f8 15 00 00 02 bb 71 15 00 00 02 bc e9 15 00 00 02 bd ed 15 00 00 02 be 67 15 00 00 02 bf e4 15 00 00 02 c0 25 15 00 00 02 c1 63 15 00 00 02 c2 84 15 00 00 02 c3 9c 15 00 00 02 c4 a6 15 00 00 02 c5 b1 15 00 00 02 c6 bd 15 00 00 02 c7 c4 15 00 00 02 c8 c8 15 00 00 02 c9 00 15 00 00 02 ca 00 15 00 00 02 cb 05 15 00 00 02 cc 6b 15 00 00 02 cd ff 15 00 00 02 ce ff 15 00 00 02 b0 08 15 00 00 02 b1 04 15 00 00 02 b2 06 15 00 00 02 b3 11 15 00 00 02 b4 24 15 00 00 02 b5 38 15 00 00 02 b6 49 15 00 00 02 b7 61 15 00 00 02 b8 79 15 00 00 02 b9 b9 15 00 00 02 ba f8 15 00 00 02 bb 71 15 00 00 02 bc ea 15 00 00 02 bd ed 15 00 00 02 be 68 15 00 00 02 bf e5 15 00 00 02 c0 26 15 00 00 02 c1 64 15 00 00 02 c2 85 15 00 00 02 c3 9c 15 00 00 02 c4 a7 15 00 00 02 c5 b1 15 00 00 02 c6 bd 15 00 00 02 c7 c4 15 00 00 02 c8 c8 15 00 00 02 c9 00 15 00 00 02 ca 00 15 00 00 02 cb 05 15 00 00 02 cc 6b 15 00 00 02 cd ff 15 00 00 02 ce ff 15 00 00 02 b0 09 15 00 00 02 b1 0c 15 00 00 02 b2 0c 15 00 00 02 b3 0f 15 00 00 02 b4 23 15 00 00 02 b5 37 15 00 00 02 b6 48 15 00 00 02 b7 60 15 00 00 02 b8 77 15 00 00 02 b9 b8 15 00 00 02 ba f7 15 00 00 02 bb 6f 15 00 00 02 bc e6 15 00 00 02 bd ea 15 00 00 02 be 62 15 00 00 02 bf da 15 00 00 02 c0 1a 15 00 00 02 c1 56 15 00 00 02 c2 75 15 00 00 02 c3 91 15 00 00 02 c4 9c 15 00 00 02 c5 a5 15 00 00 02 c6 af 15 00 00 02 c7 b5 15 00 00 02 c8 b8 15 00 00 02 c9 00 15 00 00 02 ca 00 15 00 00 02 cb 05 15 00 00 02 cc 6b 15 00 00 02 cd ff 15 00 00 02 ce ff 15 00 00 02 b0 0a 15 00 00 02 b1 08 15 00 00 02 b2 08 15 00 00 02 b3 11 15 00 00 02 b4 24 15 00 00 02 b5 37 15 00 00 02 b6 48 15 00 00 02 b7 60 15 00 00 02 b8 79 15 00 00 02 b9 b9 15 00 00 02 ba f8 15 00 00 02 bb 71 15 00 00 02 bc e9 15 00 00 02 bd ed 15 00 00 02 be 67 15 00 00 02 bf e4 15 00 00 02 c0 25 15 00 00 02 c1 63 15 00 00 02 c2 84 15 00 00 02 c3 9c 15 00 00 02 c4 a6 15 00 00 02 c5 b1 15 00 00 02 c6 bd 15 00 00 02 c7 c4 15 00 00 02 c8 c8 15 00 00 02 c9 00 15 00 00 02 ca 00 15 00 00 02 cb 05 15 00 00 02 cc 6b 15 00 00 02 cd ff 15 00 00 02 ce ff 15 00 00 02 b0 0b 15 00 00 02 b1 04 15 00 00 02 b2 06 15 00 00 02 b3 11 15 00 00 02 b4 24 15 00 00 02 b5 38 15 00 00 02 b6 49 15 00 00 02 b7 61 15 00 00 02 b8 79 15 00 00 02 b9 b9 15 00 00 02 ba f8 15 00 00 02 bb 71 15 00 00 02 bc ea 15 00 00 02 bd ed 15 00 00 02 be 68 15 00 00 02 bf e5 15 00 00 02 c0 26 15 00 00 02 c1 64 15 00 00 02 c2 85 15 00 00 02 c3 9c 15 00 00 02 c4 a7 15 00 00 02 c5 b1 15 00 00 02 c6 bd 15 00 00 02 c7 c4 15 00 00 02 c8 c8 15 00 00 02 c9 00 15 00 00 02 ca 00 15 00 00 02 cb 05 15 00 00 02 cc 6b 15 00 00 02 cd ff 15 00 00 02 ce ff 15 00 00 02 b0 0c 15 00 00 02 b1 0c 15 00 00 02 b2 0c 15 00 00 02 b3 0f 15 00 00 02 b4 23 15 00 00 02 b5 37 15 00 00 02 b6 48 15 00 00 02 b7 60 15 00 00 02 b8 77 15 00 00 02 b9 b8 15 00 00 02 ba f7 15 00 00 02 bb 6f 15 00 00 02 bc e6 15 00 00 02 bd ea 15 00 00 02 be 62 15 00 00 02 bf da 15 00 00 02 c0 1a 15 00 00 02 c1 56 15 00 00 02 c2 75 15 00 00 02 c3 91 15 00 00 02 c4 9c 15 00 00 02 c5 a5 15 00 00 02 c6 af 15 00 00 02 c7 b5 15 00 00 02 c8 b8 15 00 00 02 c9 00 15 00 00 02 ca 00 15 00 00 02 cb 05 15 00 00 02 cc 6b 15 00 00 02 cd ff 15 00 00 02 ce ff 15 00 00 02 b0 00 15 00 00 02 b2 50 15 00 00 02 b3 08 15 00 00 02 b0 04 15 0a 00 02 b8 68 05 64 00 01 11 05 32 00 01 29];
			sprd,sleep-in-command = [05 0a 00 01 28 05 65 00 01 10];
			phandle = <0x1f7>;

			display-timings {

				timing0 {
					clock-frequency = <0x927c000>;
					hactive = <0x4b0>;
					vactive = <0x780>;
					hback-porch = <0xa0>;
					hfront-porch = <0x78>;
					vback-porch = <0x14>;
					vfront-porch = <0x30>;
					hsync-len = <0x30>;
					vsync-len = <0x04>;
				};
			};
		};
	};

